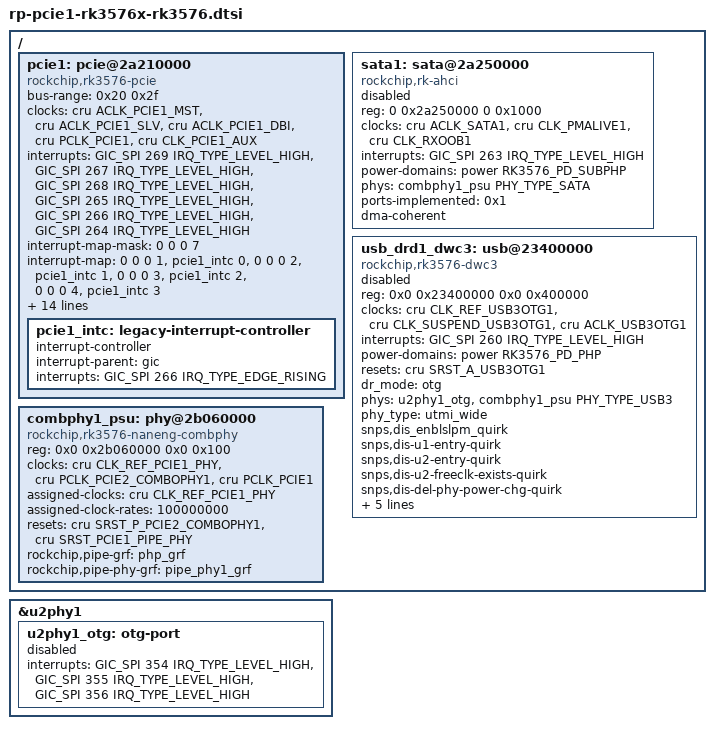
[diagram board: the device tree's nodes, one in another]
// SPDX-License-Identifier: (GPL-2.0+ OR MIT)
/*
 * Copyright (c) 2024 Rockchip Electronics Co., Ltd.
 */


/ {
	
	pcie1: pcie@2a210000 {
		compatible = "rockchip,rk3576-pcie", "snps,dw-pcie";
		#address-cells = <3>;
		#size-cells = <2>;
		bus-range = <0x20 0x2f>;
		clocks = <&cru ACLK_PCIE1_MST>, <&cru ACLK_PCIE1_SLV>,
			 <&cru ACLK_PCIE1_DBI>, <&cru PCLK_PCIE1>,
			 <&cru CLK_PCIE1_AUX>;
		clock-names = "aclk_mst", "aclk_slv",
			      "aclk_dbi", "pclk",
			      "aux";
		device_type = "pci";
		interrupts = <GIC_SPI 269 IRQ_TYPE_LEVEL_HIGH>,
			     <GIC_SPI 267 IRQ_TYPE_LEVEL_HIGH>,
			     <GIC_SPI 268 IRQ_TYPE_LEVEL_HIGH>,
			     <GIC_SPI 265 IRQ_TYPE_LEVEL_HIGH>,
			     <GIC_SPI 266 IRQ_TYPE_LEVEL_HIGH>,
			     <GIC_SPI 264 IRQ_TYPE_LEVEL_HIGH>;
		interrupt-names = "msi", "sys", "pmc", "msg", "legacy", "err";
		#interrupt-cells = <1>;
		interrupt-map-mask = <0 0 0 7>;
		interrupt-map = <0 0 0 1 &pcie1_intc 0>,
				<0 0 0 2 &pcie1_intc 1>,
				<0 0 0 3 &pcie1_intc 2>,
				<0 0 0 4 &pcie1_intc 3>;
		linux,pci-domain = <0>;
		num-ib-windows = <8>;
		num-viewport = <8>;
		num-ob-windows = <2>;
		max-link-speed = <2>;
		num-lanes = <1>;
		phys = <&combphy1_psu PHY_TYPE_PCIE>;
		phy-names = "pcie-phy";
		power-domains = <&power RK3576_PD_SUBPHP>;
		ranges = <0x00000800 0x0 0x21000000 0x0 0x21000000 0x0 0x00100000
			  0x81000000 0x0 0x21100000 0x0 0x21100000 0x0 0x00100000
			  0x82000000 0x0 0x21200000 0x0 0x21200000 0x0 0x00e00000
			  0x83000000 0x9 0x80000000 0x9 0x80000000 0x0 0x80000000>;
		reg = <0x0 0x2a210000 0x0 0x00010000>,
		      <0x0 0x22400000 0x0 0x00400000>,
		      <0x0 0x21000000 0x0 0x00100000>;
		reg-names = "pcie-apb", "pcie-dbi", "config";
		resets = <&cru SRST_PCIE1_POWER_UP>, <&cru SRST_P_PCIE1>;
		reset-names = "pipe", "p_pcie1";
		dma-coherent;
		status = "disabled";

		pcie1_intc: legacy-interrupt-controller {
			interrupt-controller;
			#address-cells = <0>;
			#interrupt-cells = <1>;
			interrupt-parent = <&gic>;
			interrupts = <GIC_SPI 266 IRQ_TYPE_EDGE_RISING>;
		};
	};
	
	
	sata1: sata@2a250000 {
		compatible = "rockchip,rk-ahci", "snps,dwc-ahci";
		reg = <0 0x2a250000 0 0x1000>;
		clocks = <&cru ACLK_SATA1>, <&cru CLK_PMALIVE1>,
			 <&cru CLK_RXOOB1>;
		clock-names = "sata", "pmalive", "rxoob";
		interrupts = <GIC_SPI 263 IRQ_TYPE_LEVEL_HIGH>;
		interrupt-names = "hostc";
		power-domains = <&power RK3576_PD_SUBPHP>;
		phys = <&combphy1_psu PHY_TYPE_SATA>;
		phy-names = "sata-phy";
		ports-implemented = <0x1>;
		dma-coherent;
		status = "disabled";
	};
	
	
	usb_drd1_dwc3: usb@23400000 {
		compatible = "rockchip,rk3576-dwc3", "snps,dwc3";
		reg = <0x0 0x23400000 0x0 0x400000>;
		clocks = <&cru CLK_REF_USB3OTG1>,
			 <&cru CLK_SUSPEND_USB3OTG1>,
			 <&cru ACLK_USB3OTG1>;
		clock-names = "ref", "suspend", "bus_clk";
		interrupts = <GIC_SPI 260 IRQ_TYPE_LEVEL_HIGH>;
		power-domains = <&power RK3576_PD_PHP>;
		resets = <&cru SRST_A_USB3OTG1>;
		reset-names = "usb3-otg";
		dr_mode = "otg";
		phys = <&u2phy1_otg>, <&combphy1_psu PHY_TYPE_USB3>;
		phy-names = "usb2-phy", "usb3-phy";
		phy_type = "utmi_wide";
		snps,dis_enblslpm_quirk;
		snps,dis-u1-entry-quirk;
		snps,dis-u2-entry-quirk;
		snps,dis-u2-freeclk-exists-quirk;
		snps,dis-del-phy-power-chg-quirk;
		snps,dis-tx-ipgap-linecheck-quirk;
		snps,dis_rxdet_inp3_quirk;
		snps,parkmode-disable-hs-quirk;
		snps,parkmode-disable-ss-quirk;
		dma-coherent;
		status = "disabled";
	};
	
	combphy1_psu: phy@2b060000 {
		compatible = "rockchip,rk3576-naneng-combphy";
		reg = <0x0 0x2b060000 0x0 0x100>;
		#phy-cells = <1>;
		clocks = <&cru CLK_REF_PCIE1_PHY>,
			 <&cru PCLK_PCIE2_COMBOPHY1>,
			 <&cru PCLK_PCIE1>;
		clock-names = "refclk", "apbclk", "pipe_clk";
		assigned-clocks = <&cru CLK_REF_PCIE1_PHY>;
		assigned-clock-rates = <100000000>;
		resets = <&cru SRST_P_PCIE2_COMBOPHY1>,
			 <&cru SRST_PCIE1_PIPE_PHY>;
		reset-names = "combphy-apb", "combphy";
		rockchip,pipe-grf = <&php_grf>;
		rockchip,pipe-phy-grf = <&pipe_phy1_grf>;
		status = "disabled";
	};
	
};



&u2phy1 {
	u2phy1_otg: otg-port {
		#phy-cells = <0>;
		interrupts = <GIC_SPI 354 IRQ_TYPE_LEVEL_HIGH>,
			     <GIC_SPI 355 IRQ_TYPE_LEVEL_HIGH>,
			     <GIC_SPI 356 IRQ_TYPE_LEVEL_HIGH>;
		interrupt-names = "otg-bvalid", "otg-id", "linestate";
		status = "disabled";
	};
};

&pcie1 {
    status = "okay";
};

&combphy1_psu {
    status = "okay";
};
